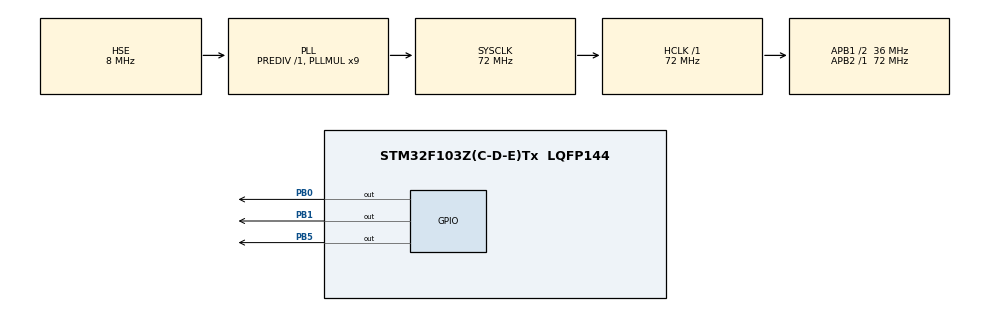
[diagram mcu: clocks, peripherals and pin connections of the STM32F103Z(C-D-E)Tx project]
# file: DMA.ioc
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Dma.MEMTOMEM.0.Direction=DMA_MEMORY_TO_MEMORY
Dma.MEMTOMEM.0.Instance=DMA1_Channel1
Dma.MEMTOMEM.0.MemDataAlignment=DMA_MDATAALIGN_WORD
Dma.MEMTOMEM.0.MemInc=DMA_MINC_ENABLE
Dma.MEMTOMEM.0.Mode=DMA_NORMAL
Dma.MEMTOMEM.0.PeriphDataAlignment=DMA_PDATAALIGN_WORD
Dma.MEMTOMEM.0.PeriphInc=DMA_PINC_ENABLE
Dma.MEMTOMEM.0.Priority=DMA_PRIORITY_LOW
Dma.Request0=MEMTOMEM
Mcu.Family=STM32F1
Mcu.Name=STM32F103Z(C-D-E)Tx
Mcu.Package=LQFP144
NVIC.PriorityGroup=NVIC_PRIORITYGROUP_4
OSC_IN.Mode=HSE-External-Oscillator
OSC_IN.Signal=RCC_OSC_IN
OSC_OUT.Mode=HSE-External-Oscillator
OSC_OUT.Signal=RCC_OSC_OUT
PB0.Signal=GPIO_Output
PB1.Signal=GPIO_Output
PB5.Signal=GPIO_Output
ProjectManager.HeapSize=0x200
ProjectManager.StackSize=0x400
ProjectManager.TargetToolchain=MDK-ARM V5
RCC.AHBFreq_Value=72000000
RCC.APB1CLKDivider=RCC_HCLK_DIV2
RCC.APB1Freq_Value=36000000
RCC.APB1TimFreq_Value=72000000
RCC.APB2Freq_Value=72000000
RCC.APB2TimFreq_Value=72000000
RCC.HCLKFreq_Value=72000000
RCC.PLLMUL=RCC_PLL_MUL9
RCC.PLLSourceVirtual=RCC_PLLSOURCE_HSE
RCC.SYSCLKFreq_VALUE=72000000
RCC.SYSCLKSource=RCC_SYSCLKSOURCE_PLLCLK
RCC.USBFreq_Value=72000000
VP_SYS_VS_ND.Mode=No_Debug
board=custom

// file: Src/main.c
/**
  ******************************************************************************
  * @file           : main.c
  * @brief          : Main program body
  ******************************************************************************
  ** This notice applies to any and all portions of this file
  * that are not between comment pairs USER CODE BEGIN and
  * USER CODE END. Other portions of this file, whether
  * inserted by the user or by software development tools
  * are owned by their respective copyright owners.
  *
  * COPYRIGHT(c) 2018 STMicroelectronics
  *
  * Redistribution and use in source and binary forms, with or without modification,
  * are permitted provided that the following conditions are met:
  *   1. Redistributions of source code must retain the above copyright notice,
  *      this list of conditions and the following disclaimer.
  *   2. Redistributions in binary form must reproduce the above copyright notice,
  *      this list of conditions and the following disclaimer in the documentation
  *      and/or other materials provided with the distribution.
  *   3. Neither the name of STMicroelectronics nor the names of its contributors
  *      may be used to endorse or promote products derived from this software
  *      without specific prior written permission.
  *
  * THIS SOFTWARE IS PROVIDED BY THE COPYRIGHT HOLDERS AND CONTRIBUTORS "AS IS"
  * AND ANY EXPRESS OR IMPLIED WARRANTIES, INCLUDING, BUT NOT LIMITED TO, THE
  * IMPLIED WARRANTIES OF MERCHANTABILITY AND FITNESS FOR A PARTICULAR PURPOSE ARE
  * DISCLAIMED. IN NO EVENT SHALL THE COPYRIGHT HOLDER OR CONTRIBUTORS BE LIABLE
  * FOR ANY DIRECT, INDIRECT, INCIDENTAL, SPECIAL, EXEMPLARY, OR CONSEQUENTIAL
  * DAMAGES (INCLUDING, BUT NOT LIMITED TO, PROCUREMENT OF SUBSTITUTE GOODS OR
  * SERVICES; LOSS OF USE, DATA, OR PROFITS; OR BUSINESS INTERRUPTION) HOWEVER
  * CAUSED AND ON ANY THEORY OF LIABILITY, WHETHER IN CONTRACT, STRICT LIABILITY,
  * OR TORT (INCLUDING NEGLIGENCE OR OTHERWISE) ARISING IN ANY WAY OUT OF THE USE
  * OF THIS SOFTWARE, EVEN IF ADVISED OF THE POSSIBILITY OF SUCH DAMAGE.
  *
  ******************************************************************************
  */
#include "main.h"
#include "stm32f1xx_hal.h"
#include "dma.h"
#include "gpio.h"

/* USER CODE BEGIN PV */
/* Private variables ---------------------------------------------------------*/
// 传输完成标志
#define DMA_FLAG_TC     DMA1_FLAG_TC6

// 要发送的数据大小
#define BUFFER_SIZE     32

/* 定义aSRC_Const_Buffer数组作为DMA传输数据源
 * const关键字将aSRC_Const_Buffer数组变量定义为常量类型
 * 表示数据存储在内部的FLASH中
 */
const uint32_t aSRC_Const_Buffer[BUFFER_SIZE]= {
                                    0x01020304,0x05060708,0x090A0B0C,0x0D0E0F10,
                                    0x11121314,0x15161718,0x191A1B1C,0x1D1E1F20,
                                    0x21222324,0x25262728,0x292A2B2C,0x2D2E2F30,
                                    0x31323334,0x35363738,0x393A3B3C,0x3D3E3F40,
                                    0x41424344,0x45464748,0x494A4B4C,0x4D4E4F50,
                                    0x51525354,0x55565758,0x595A5B5C,0x5D5E5F60,
                                    0x61626364,0x65666768,0x696A6B6C,0x6D6E6F70,
                                    0x71727374,0x75767778,0x797A7B7C,0x7D7E7F80};
/* 定义DMA传输目标存储器
 * 存储在内部的SRAM中
 */
uint32_t aDST_Buffer[BUFFER_SIZE];

/* USER CODE END PV */

void SystemClock_Config(void);

/* USER CODE BEGIN PFP */
/* Private function prototypes -----------------------------------------------*/

/* USER CODE END PFP */

/* USER CODE BEGIN 0 */
/**
  * 判断指定长度的两个数据源是否完全相等，
  * 如果完全相等返回1，只要其中一对数据不相等返回0
  */
uint8_t Buffercmp(const uint32_t* pBuffer,
                  uint32_t* pBuffer1, uint16_t BufferLength)
{
  /* 数据长度递减 */
  while(BufferLength--)
  {
    /* 判断两个数据源是否对应相等 */
    if(*pBuffer != *pBuffer1)
    {
      /* 对应数据源不相等马上退出函数，并返回0 */
      return 0;
    }
    /* 递增两个数据源的地址指针 */
    pBuffer++;
    pBuffer1++;
  }
  /* 完成判断并且对应数据相对 */
  return 1;
}
/* USER CODE END 0 */

int main(void)
{

  /* USER CODE BEGIN 1 */

  /* 定义存放比较结果变量 */
  uint8_t TransferStatus;

  /* USER CODE END 1 */

  /* MCU Configuration----------------------------------------------------------*/

  /* Reset of all peripherals, Initializes the Flash interface and the Systick. */
  HAL_Init();

  /* Configure the system clock */
  SystemClock_Config();

  /* Initialize all configured peripherals */
  MX_GPIO_Init();
  MX_DMA_Init();
  /* USER CODE BEGIN 2 */

		HAL_GPIO_WritePin(GPIOB, GPIO_PIN_0|GPIO_PIN_1|GPIO_PIN_5, GPIO_PIN_RESET);
		HAL_GPIO_WritePin(GPIOB, GPIO_PIN_0|GPIO_PIN_1|GPIO_PIN_5, GPIO_PIN_RESET); //白色

/**********************************************************************************/

//	  HAL_GPIO_WritePin(GPIOB, GPIO_PIN_0|GPIO_PIN_1|GPIO_PIN_5, GPIO_PIN_RESET);
//		HAL_GPIO_WritePin(GPIOB,GPIO_PIN_0|GPIO_PIN_1,GPIO_PIN_SET);  //红色

//		HAL_GPIO_WritePin(GPIOB, GPIO_PIN_0|GPIO_PIN_1|GPIO_PIN_5, GPIO_PIN_RESET);
//		HAL_GPIO_WritePin(GPIOB,GPIO_PIN_5,GPIO_PIN_SET);  //蓝色

//		HAL_GPIO_WritePin(GPIOB, GPIO_PIN_0|GPIO_PIN_1|GPIO_PIN_5, GPIO_PIN_RESET);
//		HAL_GPIO_WritePin(GPIOB, GPIO_PIN_0|GPIO_PIN_1|GPIO_PIN_5, GPIO_PIN_RESET); //白色

/**********************************************************************************/

delay_ms(2000);

	HAL_DMA_Start(&hdma_memtomem_dma1_channel1, (uint32_t)aSRC_Const_Buffer, (uint32_t)aDST_Buffer, BUFFER_SIZE);//开启DMA传输

//__HAL_DMA_ENABLE(&hdma_memtomem_dma1_channel1);

	  /* 等待DMA传输完成 */
  while(__HAL_DMA_GET_FLAG(&hdma_memtomem_dma1_channel1,DMA_FLAG_TC1)==RESET)
  {

  }

	  /* 比较源数据与传输后数据 */
  TransferStatus=Buffercmp(aSRC_Const_Buffer, aDST_Buffer, BUFFER_SIZE);

  /* 判断源数据与传输后数据比较结果*/
  if(TransferStatus==0)
  {
    /* 源数据与传输后数据不相等时RGB彩色灯显示红色 */
	  HAL_GPIO_WritePin(GPIOB, GPIO_PIN_0|GPIO_PIN_1|GPIO_PIN_5, GPIO_PIN_RESET);
		HAL_GPIO_WritePin(GPIOB,GPIO_PIN_0|GPIO_PIN_1,GPIO_PIN_SET);  //红色

  }
  else
  {
    /* 源数据与传输后数据相等时RGB彩色灯显示蓝色 */
		HAL_GPIO_WritePin(GPIOB, GPIO_PIN_0|GPIO_PIN_1|GPIO_PIN_5, GPIO_PIN_RESET);
		HAL_GPIO_WritePin(GPIOB,GPIO_PIN_5,GPIO_PIN_SET);  //蓝色

  }

  /* USER CODE END 2 */

  /* Infinite loop */
  while (1)
  {

//	delay_ms(1000);

  }

}

void SystemClock_Config(void)
{

  RCC_OscInitTypeDef RCC_OscInitStruct;
  RCC_ClkInitTypeDef RCC_ClkInitStruct;

    /**Initializes the CPU, AHB and APB busses clocks
    */
  RCC_OscInitStruct.OscillatorType = RCC_OSCILLATORTYPE_HSE;
  RCC_OscInitStruct.HSEState = RCC_HSE_ON;
  RCC_OscInitStruct.HSEPredivValue = RCC_HSE_PREDIV_DIV1;
  RCC_OscInitStruct.HSIState = RCC_HSI_ON;
  RCC_OscInitStruct.PLL.PLLState = RCC_PLL_ON;
  RCC_OscInitStruct.PLL.PLLSource = RCC_PLLSOURCE_HSE;
  RCC_OscInitStruct.PLL.PLLMUL = RCC_PLL_MUL9;
  if (HAL_RCC_OscConfig(&RCC_OscInitStruct) != HAL_OK)
  {
    _Error_Handler(__FILE__, __LINE__);
  }

    /**Initializes the CPU, AHB and APB busses clocks
    */
  RCC_ClkInitStruct.ClockType = RCC_CLOCKTYPE_HCLK|RCC_CLOCKTYPE_SYSCLK
                              |RCC_CLOCKTYPE_PCLK1|RCC_CLOCKTYPE_PCLK2;
  RCC_ClkInitStruct.SYSCLKSource = RCC_SYSCLKSOURCE_PLLCLK;
  RCC_ClkInitStruct.AHBCLKDivider = RCC_SYSCLK_DIV1;
  RCC_ClkInitStruct.APB1CLKDivider = RCC_HCLK_DIV2;
  RCC_ClkInitStruct.APB2CLKDivider = RCC_HCLK_DIV1;

  if (HAL_RCC_ClockConfig(&RCC_ClkInitStruct, FLASH_LATENCY_2) != HAL_OK)
  {
    _Error_Handler(__FILE__, __LINE__);
  }

    /**Configure the Systick interrupt time
    */
  HAL_SYSTICK_Config(HAL_RCC_GetHCLKFreq()/1000);

    /**Configure the Systick
    */
  HAL_SYSTICK_CLKSourceConfig(SYSTICK_CLKSOURCE_HCLK);

  /* SysTick_IRQn interrupt configuration */
  HAL_NVIC_SetPriority(SysTick_IRQn, 0, 0);
}

void _Error_Handler(char *file, int line)
{
  while(1)
  {
  }
}

/************************ (C) COPYRIGHT STMicroelectronics *****END OF FILE****/
